VERSION "HIPBNYYYYYYYYYYYYYYYYYYYYYYYYYYYYYYYYYYYYY/4/%%%/4/'%**4YYY///"

NS_ :

BS_:

BU_:

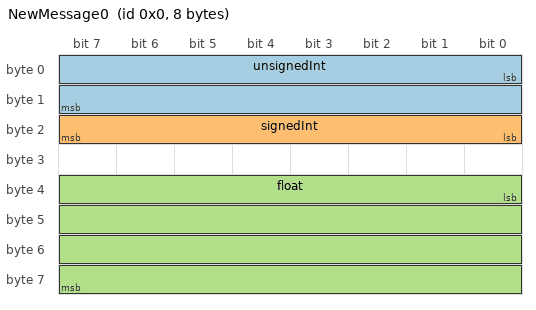
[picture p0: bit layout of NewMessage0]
BO_ 0 NewMessage0: 8 Vector__XXX
 SG_ unsignedInt : 0|16@1- (1,0) [0|0] "" Vector__XXX
 SG_ signedInt : 16|8@1+ (1,0) [0|0] "" Vector__XXX
 SG_ float : 32|32@1- (1,0) [0|0] "" Vector__XXX

BO_ 1 MessyMessage: 8 Vector__XXX
 SG_ NewSignal4 : 0|4@1+ (1,0) [0|0] "" Vector__XXX
 SG_ NewSignal5 : 8|4@1- (1,0) [0|0] "" Vector__XXX

SIG_VALTYPE_ 0 float : 1;
